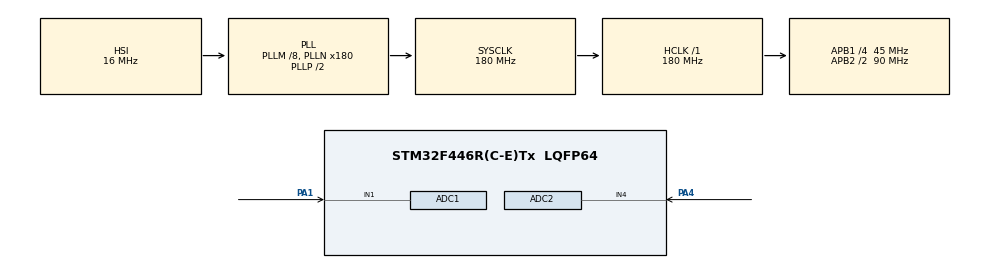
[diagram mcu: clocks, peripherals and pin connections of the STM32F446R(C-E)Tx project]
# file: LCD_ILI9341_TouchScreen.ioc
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Mcu.Family=STM32F4
PC15-OSC32_OUT.Mode=LSE-External-Oscillator
PH0-OSC_IN.Signal=RCC_OSC_IN
RCC.CortexFreq_Value=180000000
ADC1.SamplingTime-6\#ChannelRegularConversion=ADC_SAMPLETIME_3CYCLES
PA14.GPIO_Label=TCK
RCC.APB1CLKDivider=RCC_HCLK_DIV4
PC14-OSC32_IN.Signal=RCC_OSC32_IN
RCC.SYSCLKSource=RCC_SYSCLKSOURCE_PLLCLK
ProjectManager.StackSize=0x400
ADC2.Rank-7\#ChannelRegularConversion=1
PA13.Signal=SYS_JTMS-SWDIO
ProjectManager.TargetToolchain=STM32CubeIDE
RCC.HCLKFreq_Value=180000000
RCC.APB2TimFreq_Value=180000000
RCC.USBFreq_Value=180000000
PC15-OSC32_OUT.Signal=RCC_OSC32_OUT
PA1.Signal=ADCx_IN1
RCC.AHBFreq_Value=180000000
PH0-OSC_IN.Mode=HSE-External-Oscillator
RCC.HSE_VALUE=8000000
board=NUCLEO-F446RE
RCC.VCOOutputFreq_Value=360000000
ADC1.Channel-6\#ChannelRegularConversion=ADC_CHANNEL_1
RCC.APB2Freq_Value=90000000
PC14-OSC32_IN.Mode=LSE-External-Oscillator
PA14.Mode=Serial_Wire
PH1-OSC_OUT.Signal=RCC_OSC_OUT
SH.ADCx_IN4.0=ADC2_IN4,IN4
PA13.Mode=Serial_Wire
Mcu.Name=STM32F446R(C-E)Tx
PA13.GPIO_Label=TMS
RCC.FLatency-AdvancedSettings=FLASH_LATENCY_5
PH1-OSC_OUT.Mode=HSE-External-Oscillator
ADC2.SamplingTime-7\#ChannelRegularConversion=ADC_SAMPLETIME_3CYCLES
RCC.48MHZClocksFreq_Value=84000000
PB3.Signal=SYS_JTDO-SWO
PA4.Signal=ADCx_IN4
RCC.SYSCLKFreq_VALUE=180000000
Mcu.Package=LQFP64
ADC1.master=1
ADC2.NbrOfConversionFlag=1
PA14.Signal=SYS_JTCK-SWCLK
ProjectManager.HeapSize=0x200
RCC.HSI_VALUE=16000000
NVIC.PriorityGroup=NVIC_PRIORITYGROUP_0
ADC1.NbrOfConversionFlag=1
RCC.APB2CLKDivider=RCC_HCLK_DIV2
SH.ADCx_IN1.0=ADC1_IN1,IN1
RCC.PLLM=8
RCC.PLLN=180
RCC.APB1TimFreq_Value=90000000
ADC2.Channel-7\#ChannelRegularConversion=ADC_CHANNEL_4
ADC1.Rank-6\#ChannelRegularConversion=1
RCC.APB1Freq_Value=45000000
PB3.GPIO_Label=SWO

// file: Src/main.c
/* USER CODE BEGIN Header */
/**
  ******************************************************************************
  * @file           : main.c
  * @brief          : Main program body
  ******************************************************************************
  * @attention
  *
  * <h2><center>&copy; Copyright (c) 2020 STMicroelectronics.
  * All rights reserved.</center></h2>
  *
  * This software component is licensed by ST under BSD 3-Clause license,
  * the "License"; You may not use this file except in compliance with the
  * License. You may obtain a copy of the License at:
  *                        opensource.org/licenses/BSD-3-Clause
  *
  ******************************************************************************
  */
/* USER CODE END Header */
#include "main.h"
#include "adc.h"
#include "gpio.h"

/* USER CODE BEGIN Includes */
#include "lcd.h"
#include "lcd_touch.h"
/* USER CODE END Includes */

void SystemClock_Config(void);

int main(void)
{

  /* MCU Configuration--------------------------------------------------------*/

  /* Reset of all peripherals, Initializes the Flash interface and the Systick. */
  HAL_Init();

  /* Configure the system clock */
  SystemClock_Config();

  /* Initialize all configured peripherals */
  MX_GPIO_Init();
  MX_ADC1_Init();
  MX_ADC2_Init();
  /* USER CODE BEGIN 2 */

	LCD_Init();
	LCD_FillScreen(BLACK);
	LCD_SetTextSize(1);  // Font12
	LCD_SetTextScaled(0);  // don't scale the text size by 2
	LCD_SetTextColor(GREEN, BLACK);

	LCD_Touch_Init(&hadc2, ADC_CHANNEL_4, &hadc1, ADC_CHANNEL_1);
	LCD_SetMode(LCD_MODE_TOUCH);
	LCD_TouchPoint p;
  /* USER CODE END 2 */

  /* Infinite loop */
  /* USER CODE BEGIN WHILE */

  while (1)
  {
	  if (LCD_Touch_Read(&p) == LCD_TOUCH_READ_SUCCESS) {
		  LCD_Touch_Draw_ConnectLastPoint(&p);
		  LCD_Touch_Draw_PrintInfo();
	  }
	  LCD_Touch_Draw_Update();
    /* USER CODE END WHILE */

  }
}

void SystemClock_Config(void)
{
  RCC_OscInitTypeDef RCC_OscInitStruct = {0};
  RCC_ClkInitTypeDef RCC_ClkInitStruct = {0};

  /** Configure the main internal regulator output voltage
  */
  __HAL_RCC_PWR_CLK_ENABLE();
  __HAL_PWR_VOLTAGESCALING_CONFIG(PWR_REGULATOR_VOLTAGE_SCALE1);
  /** Initializes the RCC Oscillators according to the specified parameters
  * in the RCC_OscInitTypeDef structure.
  */
  RCC_OscInitStruct.OscillatorType = RCC_OSCILLATORTYPE_HSI;
  RCC_OscInitStruct.HSIState = RCC_HSI_ON;
  RCC_OscInitStruct.HSICalibrationValue = RCC_HSICALIBRATION_DEFAULT;
  RCC_OscInitStruct.PLL.PLLState = RCC_PLL_ON;
  RCC_OscInitStruct.PLL.PLLSource = RCC_PLLSOURCE_HSI;
  RCC_OscInitStruct.PLL.PLLM = 8;
  RCC_OscInitStruct.PLL.PLLN = 180;
  RCC_OscInitStruct.PLL.PLLP = RCC_PLLP_DIV2;
  RCC_OscInitStruct.PLL.PLLQ = 2;
  RCC_OscInitStruct.PLL.PLLR = 2;
  if (HAL_RCC_OscConfig(&RCC_OscInitStruct) != HAL_OK)
  {
    Error_Handler();
  }
  /** Activate the Over-Drive mode
  */
  if (HAL_PWREx_EnableOverDrive() != HAL_OK)
  {
    Error_Handler();
  }
  /** Initializes the CPU, AHB and APB buses clocks
  */
  RCC_ClkInitStruct.ClockType = RCC_CLOCKTYPE_HCLK|RCC_CLOCKTYPE_SYSCLK
                              |RCC_CLOCKTYPE_PCLK1|RCC_CLOCKTYPE_PCLK2;
  RCC_ClkInitStruct.SYSCLKSource = RCC_SYSCLKSOURCE_PLLCLK;
  RCC_ClkInitStruct.AHBCLKDivider = RCC_SYSCLK_DIV1;
  RCC_ClkInitStruct.APB1CLKDivider = RCC_HCLK_DIV4;
  RCC_ClkInitStruct.APB2CLKDivider = RCC_HCLK_DIV2;

  if (HAL_RCC_ClockConfig(&RCC_ClkInitStruct, FLASH_LATENCY_5) != HAL_OK)
  {
    Error_Handler();
  }
}

void Error_Handler(void)
{
}

#ifdef  USE_FULL_ASSERT
/**
  * @brief  Reports the name of the source file and the source line number
  *         where the assert_param error has occurred.
  * @param  file: pointer to the source file name
  * @param  line: assert_param error line source number
  * @retval None
  */
void assert_failed(uint8_t *file, uint32_t line)
{
  /* USER CODE BEGIN 6 */
  /* User can add his own implementation to report the file name and line number,
     tex: printf("Wrong parameters value: file %s on line %d\r\n", file, line) */
	LCD_SetMode(LCD_MODE_DRAW);
	LCD_SetTextColor(RED, BLACK);
	LCD_Printf("assert_failed: %s, line %lu\n", file, line);
	while (1);
  /* USER CODE END 6 */
}
#endif /* USE_FULL_ASSERT */

/************************ (C) COPYRIGHT STMicroelectronics *****END OF FILE****/
